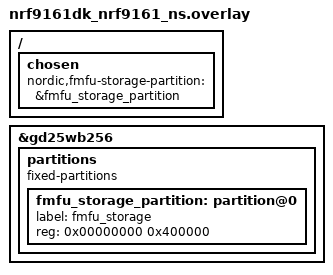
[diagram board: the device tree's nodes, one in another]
/*
 * Copyright (c) 2025 Nordic Semiconductor ASA
 *
 * SPDX-License-Identifier: LicenseRef-Nordic-5-Clause
 */

/ {
	chosen {
		nordic,fmfu-storage-partition = &fmfu_storage_partition;
	};
};

#include <samples/cellular/nrf91_immutable_bootloader_partitions.dtsi>

/* External flash device is disabled by default */
&gd25wb256 {
	status = "okay";

	partitions {
		compatible = "fixed-partitions";
		#address-cells = <1>;
		#size-cells = <1>;

		fmfu_storage_partition: partition@0 {
			label = "fmfu_storage";
			reg = <0x00000000 0x400000>;
		};
	};
};

#include <samples/cellular/nrf91_sram_partitions.dtsi>
